# FictionalDevice register map
Vendor: FictionalVendor
CPU: little endian
Registers are 16-bit, read-write, reset 0x0 unless marked. A register's access mark holds for its fields unless they carry their own. Offsets are from the block's base; lines under a group give offsets from that group; [hi:lo] are bit positions; {n}, {i} and the like mark numbered series; 'fields as' and 'values as' point back to an identical list; <NAME> marks a mode.

## Memory map
0x50000000 PORT
0x50001000 OTHER
0x50002000 NEXT
0x50003000 FINAL

## PORT
Base 0x50000000
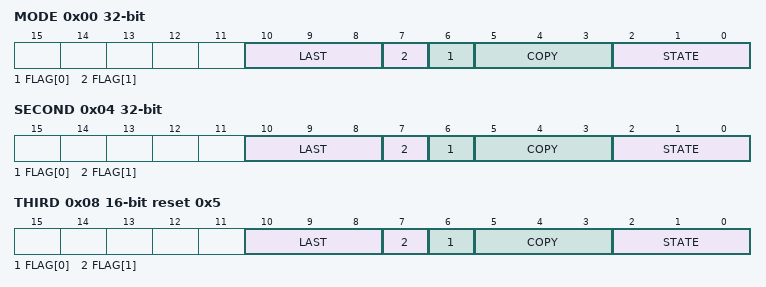
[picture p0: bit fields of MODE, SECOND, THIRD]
0x00 MODE 32-bit
  [10:8] LAST
    on read: 0=ZERO; 1=ONE; 2=TWO; 3=THREE; 0b1xx=IGNORED; other=OTHER
  [n+6] FLAG[{n}] (n=0..1)
  [5:3] COPY
    values as LAST
  [2:0] STATE
    on read: 0=ZERO; 1=ONE; 2=TWO; 3=THREE; 0b1xx=IGNORED; other=OTHER | on write: 1=WRITE_ONLY
0x04 SECOND 32-bit
  fields as MODE
0x08 THIRD reset 0x5
  fields as MODE
{0x10+4i} DATA[{i}] (i=0..1) 32-bit
0x20 LETTER{x} (x=A,B,C,D; step 0x4) 32-bit
0x30 ITEM{x} (x=A,B,C; step 0x4) 32-bit
{0x80+0x40*i} GROUP[{i}] (i=0..1) group
  {0x4+8j} INNER{j} (j=0..1) group
    0x02 VALUE
0x100 CLONE[{i}] (i=0..0; step ?) group
  {0x4+8j} INNER{j} (j=0..1) group
    0x02 VALUE
0x140 CHAIN group
  {0x4+8j} INNER{j} (j=0..1) group
    0x02 VALUE
0x190 HAZARD 32-bit read-clears
0x194 FIELD_HAZARD 32-bit
  [0] EVENT read-has-side-effects
0x10000000 OUTSIDE 32-bit

## OTHER
Base 0x50001000
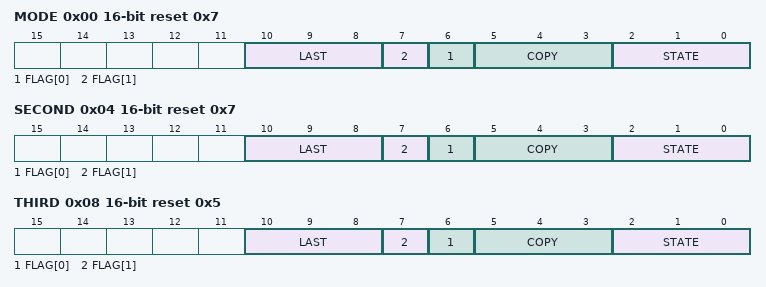
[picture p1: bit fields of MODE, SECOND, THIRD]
0x00 MODE reset 0x7
  fields as PORT.MODE
0x04 SECOND reset 0x7
  fields as PORT.MODE
0x08 THIRD reset 0x5
  fields as PORT.MODE
{0x10+4i} DATA[{i}] (i=0..1) reset 0x7
0x20 LETTER{x} (x=A,B,C,D; step 0x4) reset 0x7
0x30 ITEM{x} (x=A,B,C; step 0x4) reset 0x7
{0x80+0x40*i} GROUP[{i}] (i=0..1) group
  {0x4+8j} INNER{j} (j=0..1) group
    0x02 VALUE reset 0x7
0x100 CLONE[{i}] (i=0..0; step ?) group
  {0x4+8j} INNER{j} (j=0..1) group
    0x02 VALUE reset 0x7
0x140 CHAIN group
  {0x4+8j} INNER{j} (j=0..1) group
    0x02 VALUE reset 0x7
0x190 HAZARD reset 0x7 read-clears
0x194 FIELD_HAZARD reset 0x7
  [0] EVENT read-has-side-effects
0x10000000 OUTSIDE reset 0x7

## NEXT
Base 0x50002000
Same registers: FINAL 0x50003000
Registers as PORT; these are added or differ:
0x200 EXTRA 32-bit
